AUTOSAR XML (schema 00046)
package /VRM_VoltSts_pkg/VRM_VoltSts_imp
  swc implementation VRM_VoltSts: behavior=VRM_VoltSts
    code-descriptors:
      code Default: artifact-descriptors=autosar-engineering-object=category=SWSRC
package /VRM_VoltSts_pkg/VRM_VoltSts_swc
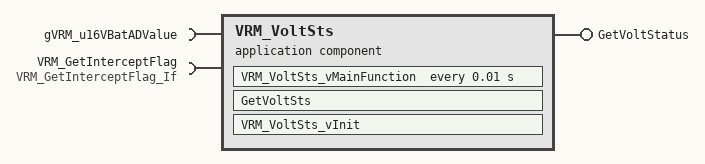
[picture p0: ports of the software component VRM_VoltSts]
  application sw component type VRM_VoltSts
    provide port GetVoltStatus: server-com-spec{operation=Operation, queue-length=1}, provided-interface=GetVoltStatus
    require port gVRM_u16VBatADValue: nonqueued-receiver-com-spec{data-element=Val, alive-timeout=60, filter=data-filter-type=ALWAYS, init-value=constant-reference=DefaultInitValue_UInt16}, required-interface=gVRM_u16VBatADValue
    require port VRM_GetInterceptFlag: client-com-spec=Operation, required-interface=VRM_GetInterceptFlag_If
    behavior VRM_VoltSts
      operation invoked event OIT_GetVoltSts_GetVoltStatus_Operation: start-on-event=GetVoltSts, operation=GetVoltStatus.Operation
      timing event PeriodicEvent: start-on-event=VRM_VoltSts_vMainFunction, period=0.01
      port-api-options:
        enable-take-address=false, error-handling=NO-TRANSFORMER-ERROR-HANDLING, indirect-api=false, port=GetVoltStatus
        enable-take-address=false, error-handling=NO-TRANSFORMER-ERROR-HANDLING, indirect-api=false, port=gVRM_u16VBatADValue
        enable-take-address=true, error-handling=NO-TRANSFORMER-ERROR-HANDLING, indirect-api=false, port=VRM_GetInterceptFlag
      runnable GetVoltSts
      runnable VRM_VoltSts_vInit
      runnable VRM_VoltSts_vMainFunction
        data-receive-point-by-arguments:
          access REC_gVRM_u16VBatADValue_Val: accessed-variable=gVRM_u16VBatADValue.Val
        sync call SC_VRM_GetInterceptFlag_Operation: operation=VRM_GetInterceptFlag.Operation
